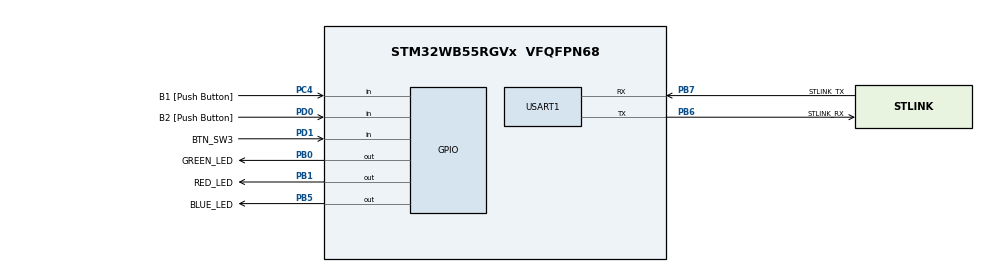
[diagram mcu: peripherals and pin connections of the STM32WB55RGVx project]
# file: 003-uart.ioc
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Mcu.Family=STM32WB
Mcu.Name=STM32WB55RGVx
Mcu.Package=VFQFPN68
NVIC.PriorityGroup=NVIC_PRIORITYGROUP_4
OSC_IN.GPIO_Label=RCC_OSC_IN
OSC_IN.Mode=HSE-External-Oscillator
OSC_IN.Signal=RCC_OSC_IN
OSC_OUT.GPIO_Label=RCC_OSC_OUT
OSC_OUT.Mode=HSE-External-Oscillator
OSC_OUT.Signal=RCC_OSC_OUT
PA11.GPIO_Label=USB_DM
PA11.Signal=USB_DM
PA12.GPIO_Label=USB_DP
PA12.Signal=USB_DP
PA13.GPIO_Label=JTMS
PA13.Signal=SYS_JTMS-SWDIO
PA14.GPIO_Label=JTCK
PA14.Signal=SYS_JTCK-SWCLK
PB0.GPIO_Label=GREEN_LED
PB0.Signal=GPIO_Output
PB1.GPIO_Label=RED_LED
PB1.Signal=GPIO_Output
PB3.GPIO_Label=JTDO
PB3.Signal=SYS_JTDO-SWO
PB5.GPIO_Label=BLUE_LED
PB5.Signal=GPIO_Output
PB6.GPIO_Label=STLINK_RX
PB6.Mode=Asynchronous
PB6.Signal=USART1_TX
PB7.GPIO_Label=STLINK_TX
PB7.Mode=Asynchronous
PB7.Signal=USART1_RX
PC13.GPIO_Label=SYS_WKUP2
PC13.Signal=SYS_WKUP2
PC14-OSC32_IN.GPIO_Label=RCC_OSC32_IN
PC14-OSC32_IN.Signal=RCC_OSC32_IN
PC15-OSC32_OUT.GPIO_Label=RCC_OSC32_OUT
PC15-OSC32_OUT.Signal=RCC_OSC32_OUT
PC4.GPIO_Label=B1 [Push Button]
PC4.Signal=GPIO_Input
PD0.GPIO_Label=B2 [Push Button]
PD0.Signal=GPIO_Input
PD1.GPIO_Label=BTN_SW3
PD1.Signal=GPIO_Input
ProjectManager.HeapSize=0x200
ProjectManager.StackSize=0x400
ProjectManager.TargetToolchain=STM32CubeIDE
RCC.ADCFreq_Value=16000000
RCC.AHB2CLKDivider=RCC_SYSCLK_DIV2
RCC.AHBFreq_Value=64000000
RCC.APB1Freq_Value=64000000
RCC.APB1TimFreq_Value=64000000
RCC.APB2Freq_Value=64000000
RCC.APB2TimFreq_Value=64000000
RCC.APB3Freq_Value=16000000
RCC.Cortex2_Div=SYSTICK_CLKSOURCE_HCLK_DIV8
RCC.CortexFreq_Value=64000000
RCC.HCLKFreq_Value=64000000
RCC.HSE_VALUE=32000000
RCC.HSI48_VALUE=48000000
RCC.HSI_VALUE=16000000
RCC.LSE_VALUE=32768
RCC.PLLN=32
RCC.SMPSCLockSelection=RCC_SMPSCLKSOURCE_HSI
RCC.SMPSCLockSelectionVirtual=RCC_SMPSCLKSOURCE_HSI
RCC.SMPSCLockSelectionVirtualVirtual=RCC_SMPSCLKSOURCE_HSI
RCC.SMPSDivider=1
RCC.SYSCLKFreq_VALUE=64000000
RCC.SYSCLKSource=RCC_SYSCLKSOURCE_PLLCLK
RCC.USBFreq_Value=16000000
RCC.VCOOutputFreq_Value=128000000
USART1.VirtualMode-Asynchronous=VM_ASYNC
VP_MEMORYMAP_VS_MEMORYMAP.Mode=CurAppReg
board=NUCLEO-WB55RG

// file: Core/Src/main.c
/* USER CODE BEGIN Header */
/**
  ******************************************************************************
  * @file           : main.c
  * @brief          : Main program body
  ******************************************************************************
  * @attention
  *
  * Copyright (c) 2025 STMicroelectronics.
  * All rights reserved.
  *
  * This software is licensed under terms that can be found in the LICENSE file
  * in the root directory of this software component.
  * If no LICENSE file comes with this software, it is provided AS-IS.
  *
  ******************************************************************************
  */
#include <stdio.h>
/* USER CODE END Header */
#include "main.h"

UART_HandleTypeDef huart1;

void SystemClock_Config(void);
void PeriphCommonClock_Config(void);
static void MX_GPIO_Init(void);
static void MX_USART1_UART_Init(void);

/* USER CODE BEGIN 0 */
int __io_putchar(int ch)
{
  HAL_UART_Transmit(&huart1, (uint8_t*)&ch, 1, 10);
  return ch;
}
/* USER CODE END 0 */

int main(void)
{

  /* MCU Configuration--------------------------------------------------------*/

  /* Reset of all peripherals, Initializes the Flash interface and the Systick. */
  HAL_Init();

  /* Configure the system clock */
  SystemClock_Config();

  /* Configure the peripherals common clocks */
  PeriphCommonClock_Config();

  /* Initialize all configured peripherals */
  MX_GPIO_Init();
  MX_USART1_UART_Init();
  /* USER CODE BEGIN 2 */

  printf("Hello from nucleo-wb55\n\r");
  HAL_Delay(500);
  /* USER CODE END 2 */

  /* Infinite loop */
  while (1)
  {
    printf("Hello from nucleo-wb55\n\r");
    HAL_Delay(500);
  }
}

void SystemClock_Config(void)
{
  RCC_OscInitTypeDef RCC_OscInitStruct = {0};
  RCC_ClkInitTypeDef RCC_ClkInitStruct = {0};

  /** Configure the main internal regulator output voltage
  */
  __HAL_PWR_VOLTAGESCALING_CONFIG(PWR_REGULATOR_VOLTAGE_SCALE1);

  /** Initializes the RCC Oscillators according to the specified parameters
  * in the RCC_OscInitTypeDef structure.
  */
  RCC_OscInitStruct.OscillatorType = RCC_OSCILLATORTYPE_HSI|RCC_OSCILLATORTYPE_HSE
                              |RCC_OSCILLATORTYPE_MSI;
  RCC_OscInitStruct.HSEState = RCC_HSE_ON;
  RCC_OscInitStruct.HSIState = RCC_HSI_ON;
  RCC_OscInitStruct.MSIState = RCC_MSI_ON;
  RCC_OscInitStruct.HSICalibrationValue = RCC_HSICALIBRATION_DEFAULT;
  RCC_OscInitStruct.MSICalibrationValue = RCC_MSICALIBRATION_DEFAULT;
  RCC_OscInitStruct.MSIClockRange = RCC_MSIRANGE_6;
  RCC_OscInitStruct.PLL.PLLState = RCC_PLL_ON;
  RCC_OscInitStruct.PLL.PLLSource = RCC_PLLSOURCE_MSI;
  RCC_OscInitStruct.PLL.PLLM = RCC_PLLM_DIV1;
  RCC_OscInitStruct.PLL.PLLN = 32;
  RCC_OscInitStruct.PLL.PLLP = RCC_PLLP_DIV2;
  RCC_OscInitStruct.PLL.PLLR = RCC_PLLR_DIV2;
  RCC_OscInitStruct.PLL.PLLQ = RCC_PLLQ_DIV2;
  if (HAL_RCC_OscConfig(&RCC_OscInitStruct) != HAL_OK)
  {
    Error_Handler();
  }

  /** Configure the SYSCLKSource, HCLK, PCLK1 and PCLK2 clocks dividers
  */
  RCC_ClkInitStruct.ClockType = RCC_CLOCKTYPE_HCLK4|RCC_CLOCKTYPE_HCLK2
                              |RCC_CLOCKTYPE_HCLK|RCC_CLOCKTYPE_SYSCLK
                              |RCC_CLOCKTYPE_PCLK1|RCC_CLOCKTYPE_PCLK2;
  RCC_ClkInitStruct.SYSCLKSource = RCC_SYSCLKSOURCE_PLLCLK;
  RCC_ClkInitStruct.AHBCLKDivider = RCC_SYSCLK_DIV1;
  RCC_ClkInitStruct.APB1CLKDivider = RCC_HCLK_DIV1;
  RCC_ClkInitStruct.APB2CLKDivider = RCC_HCLK_DIV1;
  RCC_ClkInitStruct.AHBCLK2Divider = RCC_SYSCLK_DIV2;
  RCC_ClkInitStruct.AHBCLK4Divider = RCC_SYSCLK_DIV1;

  if (HAL_RCC_ClockConfig(&RCC_ClkInitStruct, FLASH_LATENCY_3) != HAL_OK)
  {
    Error_Handler();
  }
}

void PeriphCommonClock_Config(void)
{
  RCC_PeriphCLKInitTypeDef PeriphClkInitStruct = {0};

  /** Initializes the peripherals clock
  */
  PeriphClkInitStruct.PeriphClockSelection = RCC_PERIPHCLK_SMPS;
  PeriphClkInitStruct.SmpsClockSelection = RCC_SMPSCLKSOURCE_HSI;
  PeriphClkInitStruct.SmpsDivSelection = RCC_SMPSCLKDIV_RANGE0;

  if (HAL_RCCEx_PeriphCLKConfig(&PeriphClkInitStruct) != HAL_OK)
  {
    Error_Handler();
  }
}

static void MX_USART1_UART_Init(void)
{

  huart1.Instance = USART1;
  huart1.Init.BaudRate = 115200;
  huart1.Init.WordLength = UART_WORDLENGTH_8B;
  huart1.Init.StopBits = UART_STOPBITS_1;
  huart1.Init.Parity = UART_PARITY_NONE;
  huart1.Init.Mode = UART_MODE_TX_RX;
  huart1.Init.HwFlowCtl = UART_HWCONTROL_NONE;
  huart1.Init.OverSampling = UART_OVERSAMPLING_16;
  huart1.Init.OneBitSampling = UART_ONE_BIT_SAMPLE_DISABLE;
  huart1.Init.ClockPrescaler = UART_PRESCALER_DIV1;
  huart1.AdvancedInit.AdvFeatureInit = UART_ADVFEATURE_NO_INIT;
  if (HAL_UART_Init(&huart1) != HAL_OK)
  {
    Error_Handler();
  }
  if (HAL_UARTEx_SetTxFifoThreshold(&huart1, UART_TXFIFO_THRESHOLD_1_8) != HAL_OK)
  {
    Error_Handler();
  }
  if (HAL_UARTEx_SetRxFifoThreshold(&huart1, UART_RXFIFO_THRESHOLD_1_8) != HAL_OK)
  {
    Error_Handler();
  }
  if (HAL_UARTEx_DisableFifoMode(&huart1) != HAL_OK)
  {
    Error_Handler();
  }

}

static void MX_GPIO_Init(void)
{
  GPIO_InitTypeDef GPIO_InitStruct = {0};

  /* GPIO Ports Clock Enable */
  __HAL_RCC_GPIOC_CLK_ENABLE();
  __HAL_RCC_GPIOB_CLK_ENABLE();
  __HAL_RCC_GPIOA_CLK_ENABLE();
  __HAL_RCC_GPIOD_CLK_ENABLE();

  /*Configure GPIO pin Output Level */
  HAL_GPIO_WritePin(GPIOB, GREEN_LED_Pin|RED_LED_Pin|BLUE_LED_Pin, GPIO_PIN_RESET);

  /*Configure GPIO pin : B1_Pin */
  GPIO_InitStruct.Pin = B1_Pin;
  GPIO_InitStruct.Mode = GPIO_MODE_INPUT;
  GPIO_InitStruct.Pull = GPIO_NOPULL;
  HAL_GPIO_Init(B1_GPIO_Port, &GPIO_InitStruct);

  /*Configure GPIO pins : GREEN_LED_Pin RED_LED_Pin BLUE_LED_Pin */
  GPIO_InitStruct.Pin = GREEN_LED_Pin|RED_LED_Pin|BLUE_LED_Pin;
  GPIO_InitStruct.Mode = GPIO_MODE_OUTPUT_PP;
  GPIO_InitStruct.Pull = GPIO_NOPULL;
  GPIO_InitStruct.Speed = GPIO_SPEED_FREQ_LOW;
  HAL_GPIO_Init(GPIOB, &GPIO_InitStruct);

  /*Configure GPIO pins : USB_DM_Pin USB_DP_Pin */
  GPIO_InitStruct.Pin = USB_DM_Pin|USB_DP_Pin;
  GPIO_InitStruct.Mode = GPIO_MODE_AF_PP;
  GPIO_InitStruct.Pull = GPIO_NOPULL;
  GPIO_InitStruct.Speed = GPIO_SPEED_FREQ_LOW;
  GPIO_InitStruct.Alternate = GPIO_AF10_USB;
  HAL_GPIO_Init(GPIOA, &GPIO_InitStruct);

  /*Configure GPIO pins : B2_Pin BTN_SW3_Pin */
  GPIO_InitStruct.Pin = B2_Pin|BTN_SW3_Pin;
  GPIO_InitStruct.Mode = GPIO_MODE_INPUT;
  GPIO_InitStruct.Pull = GPIO_NOPULL;
  HAL_GPIO_Init(GPIOD, &GPIO_InitStruct);

}

void Error_Handler(void)
{
  __disable_irq();
  while (1)
  {
  }
}
